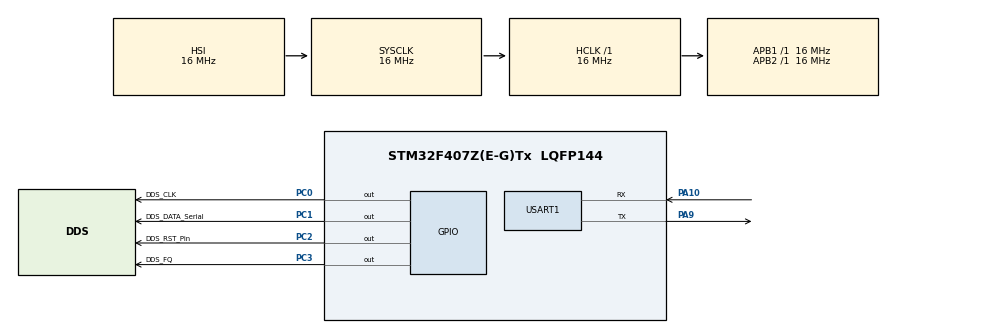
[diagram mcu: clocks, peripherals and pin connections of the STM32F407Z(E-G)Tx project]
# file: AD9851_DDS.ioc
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Mcu.Family=STM32F4
Mcu.Name=STM32F407Z(E-G)Tx
Mcu.Package=LQFP144
NVIC.PriorityGroup=NVIC_PRIORITYGROUP_4
PA10.Mode=Asynchronous
PA10.Signal=USART1_RX
PA13.Mode=Serial_Wire
PA13.Signal=SYS_JTMS-SWDIO
PA14.Mode=Serial_Wire
PA14.Signal=SYS_JTCK-SWCLK
PA9.Mode=Asynchronous
PA9.Signal=USART1_TX
PC0.GPIO_Label=DDS_CLK
PC0.GPIO_Speed=GPIO_SPEED_FREQ_HIGH
PC0.Signal=GPIO_Output
PC1.GPIO_Label=DDS_DATA_Serial
PC1.GPIO_Speed=GPIO_SPEED_FREQ_HIGH
PC1.Signal=GPIO_Output
PC2.GPIO_Label=DDS_RST_Pin
PC2.GPIO_Speed=GPIO_SPEED_FREQ_HIGH
PC2.Signal=GPIO_Output
PC3.GPIO_Label=DDS_FQ
PC3.GPIO_Speed=GPIO_SPEED_FREQ_HIGH
PC3.Signal=GPIO_Output
PH0-OSC_IN.Mode=HSE-External-Oscillator
PH0-OSC_IN.Signal=RCC_OSC_IN
PH1-OSC_OUT.Mode=HSE-External-Oscillator
PH1-OSC_OUT.Signal=RCC_OSC_OUT
ProjectManager.HeapSize=0x200
ProjectManager.StackSize=0x400
ProjectManager.TargetToolchain=MDK-ARM V5.32
RCC.AHBFreq_Value=16000000
RCC.APB1Freq_Value=16000000
RCC.APB2Freq_Value=16000000
RCC.CortexFreq_Value=16000000
RCC.HSE_VALUE=25000000
RCC.HSI_VALUE=16000000
RCC.LSE_VALUE=32768
RCC.SYSCLKFreq_VALUE=16000000
RCC.VCOOutputFreq_Value=192000000
USART1.VirtualMode=VM_ASYNC
board=custom

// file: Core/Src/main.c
/* USER CODE BEGIN Header */
/**
  ******************************************************************************
  * @file           : main.c
  * @brief          : Main program body
  ******************************************************************************
  * @attention
  *
  * Copyright (c) 2024 STMicroelectronics.
  * All rights reserved.
  *
  * This software is licensed under terms that can be found in the LICENSE file
  * in the root directory of this software component.
  * If no LICENSE file comes with this software, it is provided AS-IS.
  *
  ******************************************************************************
  */
/* USER CODE END Header */
#include "main.h"
#include "usart.h"
#include "gpio.h"

/* USER CODE BEGIN Includes */
#include <AD985x.h>
/* USER CODE END Includes */

void SystemClock_Config(void);

int main(void)
{

  /* MCU Configuration--------------------------------------------------------*/

  /* Reset of all peripherals, Initializes the Flash interface and the Systick. */
  HAL_Init();

  /* Configure the system clock */
  SystemClock_Config();

  /* Initialize all configured peripherals */
  MX_GPIO_Init();
  MX_USART1_UART_Init();
  /* USER CODE BEGIN 2 */
  AD985x_Init(AD9851, SERIAL); // 初始化控制AD9851需要用到的IO口,设置为串行通讯
  // 程序兼容AD9850和AD9851模块及串并行通讯；填入不同参数初始化即可

  /* USER CODE END 2 */

  /* Infinite loop */
  /* USER CODE BEGIN WHILE */
	int fre = 30000000;
	int swi = 1;
  while (1)
  {
		AD985x_SetFre_Phase (fre, 8); // 设置输出频率1000Hz,相位90度
		fre += 5000 * swi;
		if(fre > 40000000) swi = -1;
		if(fre < 30000000) swi = 1;
		HAL_Delay(2);
    /* USER CODE END WHILE */

  }
}

void SystemClock_Config(void)
{
  RCC_OscInitTypeDef RCC_OscInitStruct = {0};
  RCC_ClkInitTypeDef RCC_ClkInitStruct = {0};

  /** Configure the main internal regulator output voltage
  */
  __HAL_RCC_PWR_CLK_ENABLE();
  __HAL_PWR_VOLTAGESCALING_CONFIG(PWR_REGULATOR_VOLTAGE_SCALE1);

  /** Initializes the RCC Oscillators according to the specified parameters
  * in the RCC_OscInitTypeDef structure.
  */
  RCC_OscInitStruct.OscillatorType = RCC_OSCILLATORTYPE_HSI;
  RCC_OscInitStruct.HSIState = RCC_HSI_ON;
  RCC_OscInitStruct.HSICalibrationValue = RCC_HSICALIBRATION_DEFAULT;
  RCC_OscInitStruct.PLL.PLLState = RCC_PLL_NONE;
  if (HAL_RCC_OscConfig(&RCC_OscInitStruct) != HAL_OK)
  {
    Error_Handler();
  }

  /** Initializes the CPU, AHB and APB buses clocks
  */
  RCC_ClkInitStruct.ClockType = RCC_CLOCKTYPE_HCLK|RCC_CLOCKTYPE_SYSCLK
                              |RCC_CLOCKTYPE_PCLK1|RCC_CLOCKTYPE_PCLK2;
  RCC_ClkInitStruct.SYSCLKSource = RCC_SYSCLKSOURCE_HSI;
  RCC_ClkInitStruct.AHBCLKDivider = RCC_SYSCLK_DIV1;
  RCC_ClkInitStruct.APB1CLKDivider = RCC_HCLK_DIV1;
  RCC_ClkInitStruct.APB2CLKDivider = RCC_HCLK_DIV1;

  if (HAL_RCC_ClockConfig(&RCC_ClkInitStruct, FLASH_LATENCY_0) != HAL_OK)
  {
    Error_Handler();
  }
}

void Error_Handler(void)
{
  __disable_irq();
  while (1)
  {
  }
}
